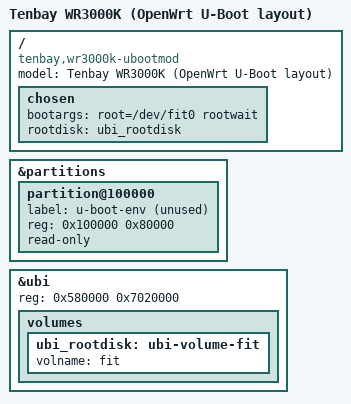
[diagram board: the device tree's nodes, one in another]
// SPDX-License-Identifier: (GPL-2.0 OR MIT)

/dts-v1/;
#include "mt7981b-tenbay-wr3000k-common.dtsi"

/ {
	model = "Tenbay WR3000K (OpenWrt U-Boot layout)";
	compatible = "tenbay,wr3000k-ubootmod", "mediatek,mt7981";

	chosen {
		bootargs = "root=/dev/fit0 rootwait";
		rootdisk = <&ubi_rootdisk>;
	};
};

&partitions {
	partition@100000 {
		label = "u-boot-env (unused)";
		reg = <0x100000 0x80000>;
		read-only;
	};
};

&ubi {
	reg = <0x580000 0x7020000>;

	volumes {
		ubi_rootdisk: ubi-volume-fit {
			volname = "fit";
		};
	};
};
